# ESP32-S31 register map
Vendor: ESPRESSIF SYSTEMS (SHANGHAI) CO., LTD.; Series: ESP32 S-Series; File version: 1
CPU: RV32IMAFC r0p0, little endian, no MPU, FPU, 0 interrupt priority bits
Address unit: 32 bits
Registers are 32-bit, read-write, reset 0x0 unless marked. A register's access mark holds for its fields unless they carry their own. Offsets are from the block's base; [hi:lo] are bit positions; lines under a group give offsets from that group; {n}, {i} and the like mark numbered series.

## IEEE802154 — IEEE802154 Peripheral
Base 0x20103000
0x00 COMMAND
  [7:0] OPCODE
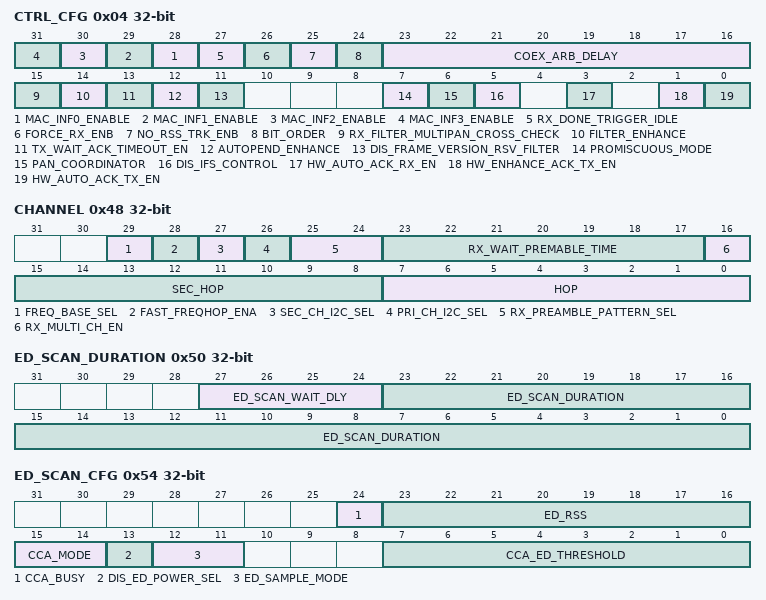
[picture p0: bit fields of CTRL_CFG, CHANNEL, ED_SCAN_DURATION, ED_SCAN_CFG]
0x04 CTRL_CFG
  [n+28] MAC_INF{n}_ENABLE (n=0..3), [27] RX_DONE_TRIGGER_IDLE, [26] FORCE_RX_ENB, [25] NO_RSS_TRK_ENB, [24] BIT_ORDER, [23:16] COEX_ARB_DELAY, [15] RX_FILTER_MULTIPAN_CROSS_CHECK, [14] FILTER_ENHANCE, [13] TX_WAIT_ACK_TIMEOUT_EN, [12] AUTOPEND_ENHANCE, [11] DIS_FRAME_VERSION_RSV_FILTER, [7] PROMISCUOUS_MODE, [6] PAN_COORDINATOR, [5] DIS_IFS_CONTROL, [3] HW_AUTO_ACK_RX_EN, [1] HW_ENHANCE_ACK_TX_EN, [0] HW_AUTO_ACK_TX_EN
{0x8+0x10*i} INF{i} (i=0..3) group — Cluster INF{i}, containing INF?_EXTEND_ADDR0, INF?_EXTEND_ADDR1, INF?_PAN_ID, INF?_SHORT_ADDR
  0x00 SHORT_ADDR — INF0_SHORT_ADDR
    [15:0] SHORT_ADDR
  0x04 PAN_ID — INF0_PAN_ID
    [15:0] PAN_ID
  0x08 EXTEND_ADDR0 — INF0_EXTEND_ADDR0
  0x0C EXTEND_ADDR1 — INF0_EXTEND_ADDR1
0x48 CHANNEL
  [29] FREQ_BASE_SEL, [28] FAST_FREQHOP_ENA, [27] SEC_CH_I2C_SEL, [26] PRI_CH_I2C_SEL, [25:24] RX_PREAMBLE_PATTERN_SEL, [23:17] RX_WAIT_PREMABLE_TIME, [16] RX_MULTI_CH_EN, [15:8] SEC_HOP, [7:0] HOP
0x4C TX_POWER
  [7:0] TX_POWER
0x50 ED_SCAN_DURATION
  [27:24] ED_SCAN_WAIT_DLY, [23:0] ED_SCAN_DURATION
0x54 ED_SCAN_CFG
  [24] CCA_BUSY, [23:16] ED_RSS, [15:14] CCA_MODE, [13] DIS_ED_POWER_SEL, [12:11] ED_SAMPLE_MODE, [7:0] CCA_ED_THRESHOLD
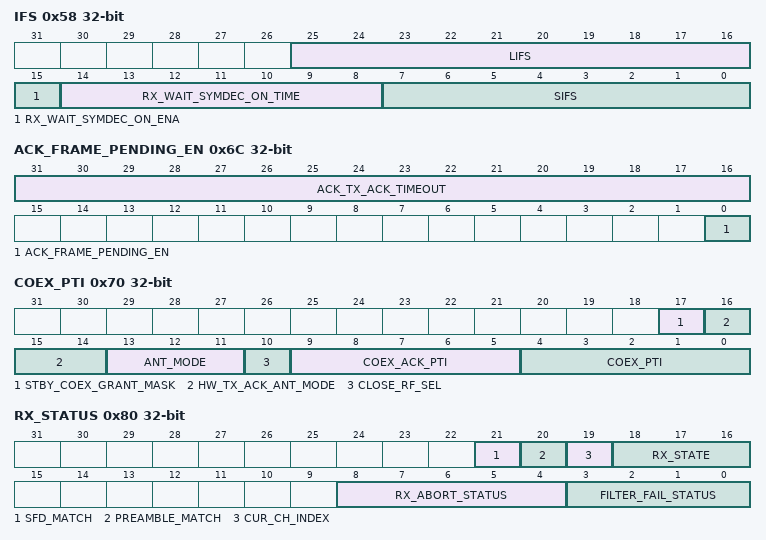
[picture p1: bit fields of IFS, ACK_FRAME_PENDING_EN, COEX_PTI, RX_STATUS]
0x58 IFS
  [25:16] LIFS, [15] RX_WAIT_SYMDEC_ON_ENA, [14:8] RX_WAIT_SYMDEC_ON_TIME, [7:0] SIFS
0x5C ACK_TIMEOUT
  [15:0] ACK_TIMEOUT
0x60 EVENT_EN
  [13:0] EVENT_EN
0x64 EVENT_STATUS
  [13:0] EVENT_STATUS
0x68 RX_ABORT_INTR_CTRL
  [30:0] RX_ABORT_INTR_CTRL
0x6C ACK_FRAME_PENDING_EN
  [31:16] ACK_TX_ACK_TIMEOUT, [0] ACK_FRAME_PENDING_EN
0x70 COEX_PTI
  [17] STBY_COEX_GRANT_MASK, [16:14] HW_TX_ACK_ANT_MODE, [13:11] ANT_MODE, [10] CLOSE_RF_SEL, [9:5] COEX_ACK_PTI, [4:0] COEX_PTI
0x78 TX_ABORT_INTERRUPT_CONTROL
  [30:0] TX_ABORT_INTERRUPT_CONTROL
0x7C ENHANCE_ACK_CFG
  [31:0] TX_ENH_ACK_GENERATE_DONE_NOTIFY
0x80 RX_STATUS
  [21] SFD_MATCH, [20] PREAMBLE_MATCH, [19] CUR_CH_INDEX, [18:16] RX_STATE, [8:4] RX_ABORT_STATUS, [3:0] FILTER_FAIL_STATUS
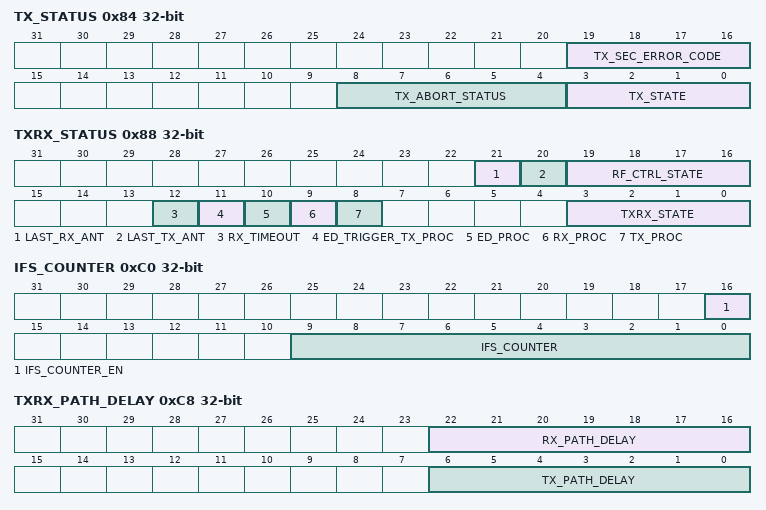
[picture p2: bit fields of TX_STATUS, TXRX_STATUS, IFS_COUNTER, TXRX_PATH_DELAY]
0x84 TX_STATUS
  [19:16] TX_SEC_ERROR_CODE, [8:4] TX_ABORT_STATUS, [3:0] TX_STATE
0x88 TXRX_STATUS
  [21] LAST_RX_ANT, [20] LAST_TX_ANT, [19:16] RF_CTRL_STATE, [12] RX_TIMEOUT, [11] ED_TRIGGER_TX_PROC, [10] ED_PROC, [9] RX_PROC, [8] TX_PROC, [3:0] TXRX_STATE
0x8C TX_CCM_SCHEDULE_STATUS
  [30:0] TX_CCM_SCHEDULE_STATUS
0xA4 RX_LENGTH
  [6:0] RX_LENGTH
{0xA8+8i} TIME{i} (i=0..1) group — Cluster TIME{i}, containing TIME?_THRESHOLD, TIME?_VALUE
  0x00 THRESHOLD — TIME0_THRESHOLD
    [31:0] TIMER0_THRESHOLD
  0x04 VALUE — TIME0_VALUE
    [31:0] TIMER0_VALUE
0xB8 CLK_COUNTER_MATCH_VAL
  [15:0] CLK_COUNT_MATCH_VAL
0xBC CLK_COUNTER
  [15:0] CLK_625US_CNT
0xC0 IFS_COUNTER
  [16] IFS_COUNTER_EN, [9:0] IFS_COUNTER
0xC4 SFD_WAIT_SYMBOL
  [3:0] SFD_WAIT_SYMBOL_NUM
0xC8 TXRX_PATH_DELAY
  [22:16] RX_PATH_DELAY, [6:0] TX_PATH_DELAY
0xCC BB_CLK
  [4:0] BB_CLK_FREQ_MINUS_1
0xD0 TXDMA_ADDR
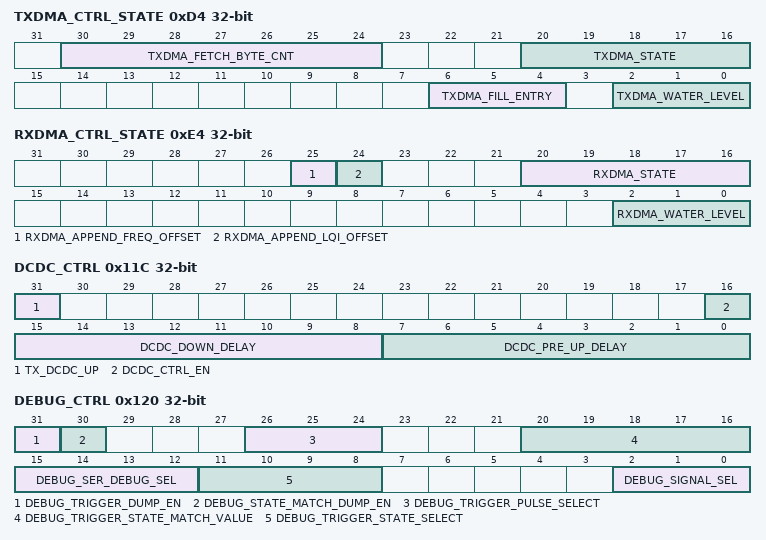
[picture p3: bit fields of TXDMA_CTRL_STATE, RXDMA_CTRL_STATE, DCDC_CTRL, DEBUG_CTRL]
0xD4 TXDMA_CTRL_STATE
  [30:24] TXDMA_FETCH_BYTE_CNT, [20:16] TXDMA_STATE, [6:4] TXDMA_FILL_ENTRY, [2:0] TXDMA_WATER_LEVEL
0xD8 TXDMA_ERR
  [3:0] TXDMA_ERR
0xE0 RXDMA_ADDR
0xE4 RXDMA_CTRL_STATE
  [25] RXDMA_APPEND_FREQ_OFFSET, [24] RXDMA_APPEND_LQI_OFFSET, [20:16] RXDMA_STATE, [2:0] RXDMA_WATER_LEVEL
0xE8 RXDMA_ERR
  [3:0] RXDMA_ERR
0xF0 DMA_GCK_CFG
  [0] DMA_GCK_CFG
0xF4 DMA_DUMMY
  [31:0] DMA_DUMMY_DATA
0x100 PAON_DELAY
  [9:0] PAON_DELAY
0x104 TXON_DELAY
  [9:0] TXON_DELAY
0x108 TXEN_STOP_DELAY
  [5:0] TXEN_STOP_DLY
0x10C TXOFF_DELAY
  [5:0] TXOFF_DELAY
0x110 RXON_DELAY
  [10:0] RXON_DELAY
0x114 TXRX_SWITCH_DELAY
  [9:0] TXRX_SWITCH_DELAY
0x118 CONT_RX_DELAY
  [5:0] CONT_RX_DELAY
0x11C DCDC_CTRL
  [31] TX_DCDC_UP, [16] DCDC_CTRL_EN, [15:8] DCDC_DOWN_DELAY, [7:0] DCDC_PRE_UP_DELAY
0x120 DEBUG_CTRL
  [31] DEBUG_TRIGGER_DUMP_EN, [30] DEBUG_STATE_MATCH_DUMP_EN, [26:24] DEBUG_TRIGGER_PULSE_SELECT, [20:16] DEBUG_TRIGGER_STATE_MATCH_VALUE, [15:12] DEBUG_SER_DEBUG_SEL, [11:8] DEBUG_TRIGGER_STATE_SELECT, [2:0] DEBUG_SIGNAL_SEL
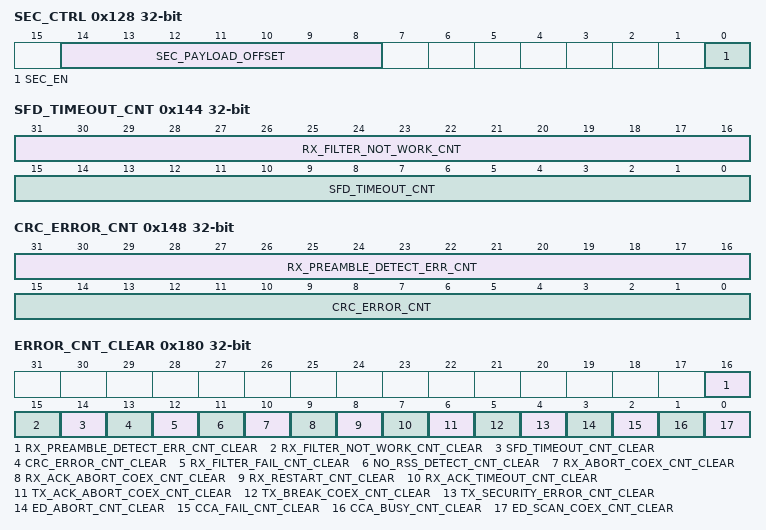
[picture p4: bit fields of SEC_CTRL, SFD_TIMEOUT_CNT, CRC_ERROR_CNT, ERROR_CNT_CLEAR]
0x128 SEC_CTRL
  [14:8] SEC_PAYLOAD_OFFSET, [0] SEC_EN
0x12C SEC_EXTEND_ADDRESS0
0x130 SEC_EXTEND_ADDRESS1
{0x134+4i} SEC_KEY{i} (i=0..3) — SEC_KEY{i}
  [31:0] SEC_KEY0
0x144 SFD_TIMEOUT_CNT
  [31:16] RX_FILTER_NOT_WORK_CNT, [15:0] SFD_TIMEOUT_CNT
0x148 CRC_ERROR_CNT
  [31:16] RX_PREAMBLE_DETECT_ERR_CNT, [15:0] CRC_ERROR_CNT
0x14C ED_ABORT_CNT
  [15:0] ED_ABORT_CNT
0x150 CCA_FAIL_CNT
  [15:0] CCA_FAIL_CNT
0x154 RX_FILTER_FAIL_CNT
  [15:0] RX_FILTER_FAIL_CNT
0x158 NO_RSS_DETECT_CNT
  [15:0] NO_RSS_DETECT_CNT
0x15C RX_ABORT_COEX_CNT
  [15:0] RX_ABORT_COEX_CNT
0x160 RX_RESTART_CNT
  [15:0] RX_RESTART_CNT
0x164 TX_ACK_ABORT_COEX_CNT
  [15:0] TX_ACK_ABORT_COEX_CNT
0x168 ED_SCAN_COEX_CNT
  [15:0] ED_SCAN_COEX_CNT
0x16C RX_ACK_ABORT_COEX_CNT
  [15:0] RX_ACK_ABORT_COEX_CNT
0x170 RX_ACK_TIMEOUT_CNT
  [15:0] RX_ACK_TIMEOUT_CNT
0x174 TX_BREAK_COEX_CNT
  [15:0] TX_BREAK_COEX_CNT
0x178 TX_SECURITY_ERROR_CNT
  [15:0] TX_SECURITY_ERROR_CNT
0x17C CCA_BUSY_CNT
  [15:0] CCA_BUSY_CNT
0x180 ERROR_CNT_CLEAR
  [16] RX_PREAMBLE_DETECT_ERR_CNT_CLEAR, [15] RX_FILTER_NOT_WORK_CNT_CLEAR, [14] SFD_TIMEOUT_CNT_CLEAR, [13] CRC_ERROR_CNT_CLEAR, [12] RX_FILTER_FAIL_CNT_CLEAR, [11] NO_RSS_DETECT_CNT_CLEAR, [10] RX_ABORT_COEX_CNT_CLEAR, [9] RX_ACK_ABORT_COEX_CNT_CLEAR, [8] RX_RESTART_CNT_CLEAR, [7] RX_ACK_TIMEOUT_CNT_CLEAR, [6] TX_ACK_ABORT_COEX_CNT_CLEAR, [5] TX_BREAK_COEX_CNT_CLEAR, [4] TX_SECURITY_ERROR_CNT_CLEAR, [3] ED_ABORT_CNT_CLEAR, [2] CCA_FAIL_CNT_CLEAR, [1] CCA_BUSY_CNT_CLEAR, [0] ED_SCAN_COEX_CNT_CLEAR
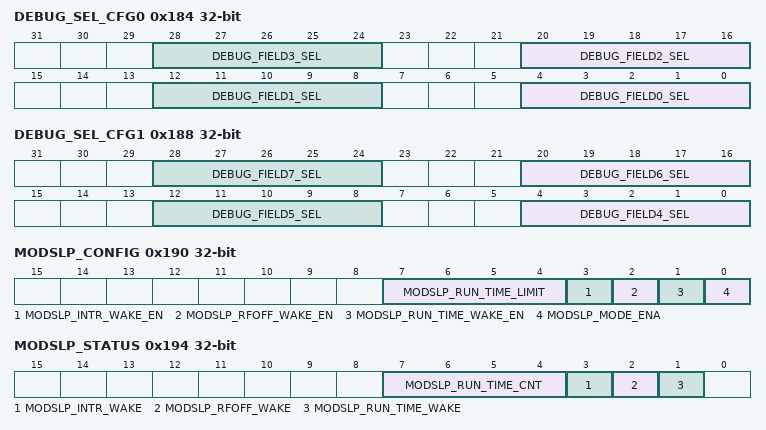
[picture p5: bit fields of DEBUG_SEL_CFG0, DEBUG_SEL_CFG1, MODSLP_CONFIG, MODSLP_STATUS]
0x184 DEBUG_SEL_CFG0
  [8n+4:8n] DEBUG_FIELD{n}_SEL (n=0..3)
0x188 DEBUG_SEL_CFG1
  [8n-28:8n-32] DEBUG_FIELD{n}_SEL (n=4..7)
0x18C RX_TIMEOUT_TARGET_CNT
  [23:0] RX_TIMEOUT_TARGET_CNT
0x190 MODSLP_CONFIG
  [7:4] MODSLP_RUN_TIME_LIMIT, [3] MODSLP_INTR_WAKE_EN, [2] MODSLP_RFOFF_WAKE_EN, [1] MODSLP_RUN_TIME_WAKE_EN, [0] MODSLP_MODE_ENA
0x194 MODSLP_STATUS
  [7:4] MODSLP_RUN_TIME_CNT, [3] MODSLP_INTR_WAKE, [2] MODSLP_RFOFF_WAKE, [1] MODSLP_RUN_TIME_WAKE
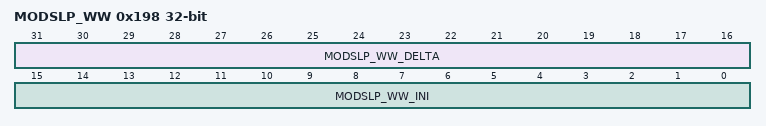
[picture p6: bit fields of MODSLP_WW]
0x198 MODSLP_WW
  [31:16] MODSLP_WW_DELTA, [15:0] MODSLP_WW_INI
0x19C MODSLP_INTR_WAKE_CONFIG
  [13:0] MODSLP_INTR_WAKE_CONFIG
0x1A0 MAC_DATE
